# STM32U345 register map
File version: 1.0
CPU: CM33 r0p1, little endian, MPU, FPU, 4 interrupt priority bits
Registers are 32-bit, read-write, reset 0x0 unless marked. A register's access mark holds for its fields unless they carry their own. Offsets are from the block's base; [hi:lo] are bit positions; {n}, {i} and the like mark numbered series; 'fields as' and 'values as' point back to an identical list.

## DBGMCU — DBGMCU address block description
Base 0xE0044000
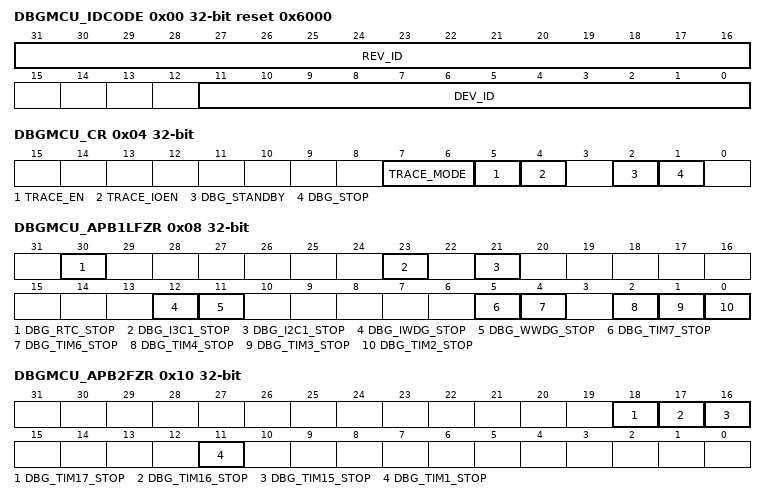
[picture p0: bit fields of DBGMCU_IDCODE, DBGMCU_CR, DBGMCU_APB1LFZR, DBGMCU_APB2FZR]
0x00 DBGMCU_IDCODE ro reset 0x6000 (reset mask 0xF000)
  [31:16] REV_ID — Revision
    0x1000=Revision A; 0x1001=Revision Z
  [11:0] DEV_ID — Device identification
    0x454=STM32U375/385; 0x42A=STM32U3B5/3C5
0x04 DBGMCU_CR
  [7:6] TRACE_MODE — Trace pin assignment
    0=Trace pins assigned for asynchronous mode (TRACESWO); 1=Trace pins assigned for synchronous mode with a port width of 1 (TRACECK, TRACED0); 2=Trace pins assigned for synchronous mode with a port width of 2 (TRACECK, TRACED0-1); 3=Trace pins assigned for synchronous mode with a port width of 4 (TRACECK, TRACED0-3)
  [5] TRACE_EN — Trace port and clock enable. This bit enables the trace port clock, TRACECK.
    0=Disabled; 1=Enabled
  [4] TRACE_IOEN — Trace pin enable
    0=Disabled - trace pins not assigned; 1=Enabled - trace pins assigned according to the value of TRACE_MODE bit field
  [2] DBG_STANDBY — Allows debug in Standby mode
    0=Normal operation. All clocks are disabled and the core powered down automatically in Standby mode.; 1=Automatic clock stop/power-down disabled. All active clocks and oscillators continue to run during Standby mode, and the core supply is maintained, allowing full debug capability. On exit from Standby mode, a system reset is performed.
  [1] DBG_STOP — Allows debug in Stop mode
    0=Normal operation. All clocks are disabled automatically in Stop mode.; 1=Automatic clock stop disabled. All active clocks and oscillators continue to run during Stop mode, allowing full debug capability. On exit from Stop mode, the clock settings are set to the Stop mode exit state.
0x08 DBGMCU_APB1LFZR
  [30] DBG_RTC_STOP — RTC stop in debug
    0=Normal operation. The RTC continues to operate while the CPU is in debug mode.; 1=Stop in debug. The RTC is frozen while the CPU is in debug mode.
  [23] DBG_I3C1_STOP — I3C1 timeout stop in debug
    0=Normal operation. I3C1 timeout continues to operate while the CPU is in debug mode.; 1=Stop in debug. I3C1 timeout is frozen while the CPU is in debug mode.
  [21] DBG_I2C1_STOP — I2C1 SMBUS timeout stop in debug
    0=Normal operation. I2C1 SMBUS timeout continues to operate while the CPU is in debug mode.; 1=Stop in debug. I2C1 SMBUS timeout is frozen while the CPU is in debug mode.
  [12] DBG_IWDG_STOP — IWDG stop in debug
    0=Normal operation. The IWDG continues to operate while the CPU is in debug mode.; 1=Stop in debug. The IWDG is frozen while the CPU is in debug mode.
  [11] DBG_WWDG_STOP — WWDG stop in debug
    0=Normal operation. The WWDG continues to operate while CPU is in debug mode.; 1=Stop in debug. The WWDG is frozen while CPU is in debug mode.
  [5] DBG_TIM7_STOP — TIMy stop in debug
    0=Normal operation. The TIMy continues to operate while the CPU is in debug mode.; 1=Stop in debug. The TIMy is frozen while the CPU is in debug mode.
  [4] DBG_TIM6_STOP — TIMy stop in debug
    values as DBG_TIM7_STOP
  [2] DBG_TIM4_STOP — TIMy stop in debug
    values as DBG_TIM7_STOP
  [1] DBG_TIM3_STOP — TIMy stop in debug
    values as DBG_TIM7_STOP
  [0] DBG_TIM2_STOP — TIMy stop in debug
    values as DBG_TIM7_STOP
0x0C DBGMCU_APB1HFZR
  [5] DBG_LPTIM2_STOP — LPTIM2 stop in debug
    0=Normal operation. The LPTIM2 continues to operate while the CPU is in debug mode.; 1=Stop in debug. The LPTIM2 is frozen while the CPU is in debug mode.
0x10 DBGMCU_APB2FZR
  [18] DBG_TIM17_STOP — TIMy stop in debug
    values as DBGMCU_APB1LFZR.DBG_TIM7_STOP
  [17] DBG_TIM16_STOP — TIMy stop in debug
    values as DBGMCU_APB1LFZR.DBG_TIM7_STOP
  [16] DBG_TIM15_STOP — TIMy stop in debug
    values as DBGMCU_APB1LFZR.DBG_TIM7_STOP
  [11] DBG_TIM1_STOP — TIM1 stop in debug
    0=Normal operation. The TIM1 continues to operate while the CPU is in debug mode.; 1=Stop in debug. The TIM1 is frozen while the CPU is in debug mode.
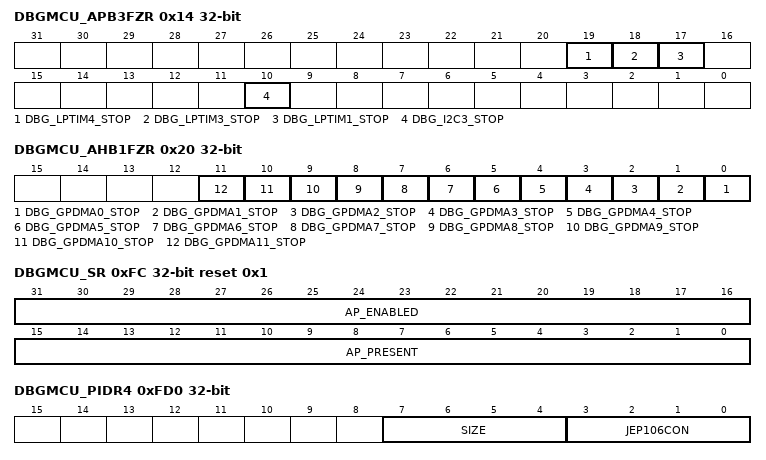
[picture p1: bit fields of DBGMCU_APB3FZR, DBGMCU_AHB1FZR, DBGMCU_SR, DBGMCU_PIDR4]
0x14 DBGMCU_APB3FZR
  [19] DBG_LPTIM4_STOP — LPTIM4 stop in debug
    0=Normal operation. The LPTIM4 continues to operate while the CPU is in debug mode.; 1=Stop in debug. The LPTIM4 is frozen while the CPU is in debug mode.
  [18] DBG_LPTIM3_STOP — LPTIM3 stop in debug
    0=Normal operation. The LPTIM3 continues to operate while the CPU is in debug mode.; 1=Stop in debug. The LPTIM3 is frozen while the CPU is in debug mode.
  [17] DBG_LPTIM1_STOP — LPTIM1 stop in debug
    0=Normal operation. The LPTIM1 continues to operate while the CPU is in debug mode.; 1=Stop in debug. The LPTIM1 is frozen while the CPU is in debug mode.
  [10] DBG_I2C3_STOP — I2C3 stop in debug
    0=Normal operation. The I2C3 continues to operate while the CPU is in debug mode.; 1=Stop in debug. The I2C3 is frozen while the CPU is in debug mode.
0x20 DBGMCU_AHB1FZR
  [all] fields
    0=normal operation. GPDMA channel y continues to operate while the CPU is in debug mode.; 1=stop in debug. GPDMA channel y is frozen while the CPU is in debug mode.
  [n] DBG_GPDMA{n}_STOP (n=0..11) — GPDMA channel y stop in debug
0xFC DBGMCU_SR ro reset 0x1 (reset mask 0xFFFF)
  [31:16] AP_ENABLED — Bit n identifies whether access port AP n is open (can be accessed via the debug port) or locked (debug access to the AP is blocked) Bit n = 0: APn locked Bit n = 1: APn enabled
  [15:0] AP_PRESENT — Bit n identifies whether access port AP n is present in device Bit n = 0: APn absent Bit n = 1: APn present
0x100 DBGMCU_DBG_AUTH_HOST wo reset not defined
  [31:0] AUTH_KEY — Device authentication key The device specific 128-bit authentication key (OEM key) must be written to this register (in four successive 32-bit writes, least significant word first) to permit RDP regression. Writing a wrong key locks access to the device, and prevent code execution from the flash memory.
0x104 DBGMCU_DBG_AUTH_DEVICE ro reset not defined
  [31:0] AUTH_ID — Device specific authentication ID Device specific authentication ID used for RDP regression.
0xFD0 DBGMCU_PIDR4 ro
  [7:4] SIZE — Register file size
    0=The register file occupies a single 4-Kbyte region
  [3:0] JEP106CON — JEP106 continuation code
    0=STMicroelectronics JEDEC code
0xFE0 DBGMCU_PIDR0 ro
  [7:0] PARTNUM — Part number bits [7:0]
    0=DBGMCU part number
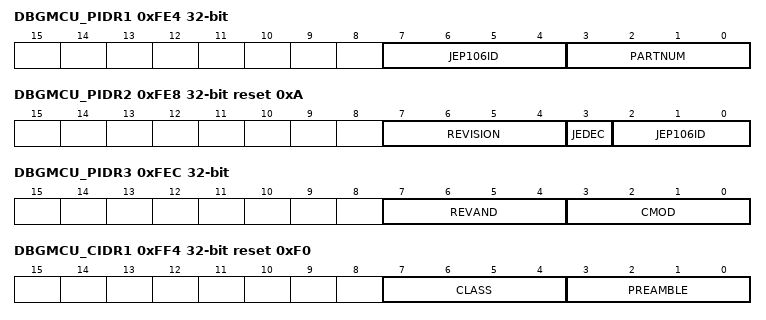
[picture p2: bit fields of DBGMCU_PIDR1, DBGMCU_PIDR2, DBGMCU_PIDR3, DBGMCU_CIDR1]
0xFE4 DBGMCU_PIDR1 ro
  [7:4] JEP106ID — JEP106 identity code bits [3:0]
    0=STMicroelectronics JEDEC code
  [3:0] PARTNUM — Part number bits [11:8]
    0=DBGMCU part number
0xFE8 DBGMCU_PIDR2 ro reset 0xA
  [7:4] REVISION — Component revision number
    0=r0p0
  [3] JEDEC — JEDEC assigned value
    1=designer identification specified by JEDEC
  [2:0] JEP106ID — JEP106 identity code bits [6:4]
    2=STMicroelectronics JEDEC code
0xFEC DBGMCU_PIDR3 ro
  [7:4] REVAND — Metal fix version
    0=No metal fix
  [3:0] CMOD — Customer modified
    0=No customer modifications
0xFF0 DBGMCU_CIDR0 ro reset 0xD
  [7:0] PREAMBLE — Component identification bits [7:0]
    13=Common identification value
0xFF4 DBGMCU_CIDR1 ro reset 0xF0
  [7:4] CLASS — Component identification bits [15:12] - component class
    15=Non-CoreSight component
  [3:0] PREAMBLE — Component identification bits [11:8]
    0=Common identification value
0xFF8 DBGMCU_CIDR2 ro reset 0x5
  [7:0] PREAMBLE — Component identification bits [23:16]
    5=Common identification value
0xFFC DBGMCU_CIDR3 ro reset 0xB1
  [7:0] PREAMBLE — Component identification bits [31:24]
    177=Common identification value
